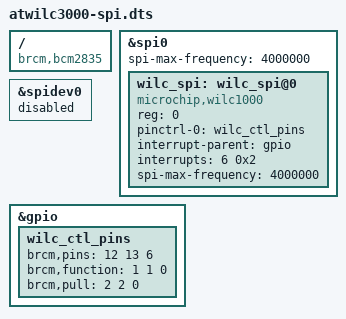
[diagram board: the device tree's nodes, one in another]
/dts-v1/;
/plugin/;

/ {
compatible = "brcm,bcm2835";

	fragment@0 {
		target = <&spi0>;
		__overlay__ {
			#address-cells = <1>;
			#size-cells = <0>;
			status = "okay";
			spi-max-frequency = <4000000>;

			wilc_spi: wilc_spi@0{
				compatible = "microchip,wilc1000", "microchip,wilc3000";
				reg = <0>;      /* CE0 */
				pinctrl-names = "default";
				pinctrl-0 = <&wilc_ctl_pins>;
				interrupt-parent = <&gpio>;
				interrupts = <6 0x2>; /* falling edge */
				spi-max-frequency = <4000000>;
				status = "okay";
			};
		};
	};

	fragment@1 {
		target = <&spidev0>;
		__overlay__ {
			status = "disabled";
		};
	};

	fragment@2 {
		target = <&gpio>;
		__overlay__ {
			wilc_ctl_pins: wilc_ctl_pins {
				brcm,pins = <12 13 6>;		/* EN, RESETN, IRQ*/
				brcm,function = <1 1 0>;	/* out */
				brcm,pull = <2 2 0>;		/* dh */
			};
		};
	};
};
